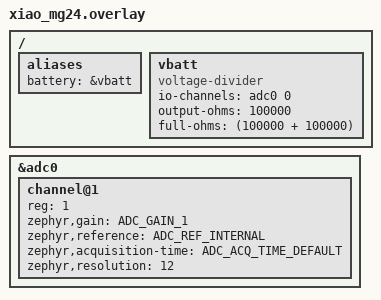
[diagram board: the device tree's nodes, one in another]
/*
 * SPDX-FileCopyrightText: Copyright The Zephyr Project Contributors
 * SPDX-License-Identifier: Apache-2.0
 */

#include <zephyr/dt-bindings/gpio/gpio.h>

/ {
	aliases {
		battery = &vbatt;
	};

	vbatt: vbatt {
		compatible = "voltage-divider";
		io-channels = <&adc0 0>;
		output-ohms = <100000>;
		full-ohms = <(100000 + 100000)>;
	};
};

&adc0 {
	status = "okay";
	#address-cells = <1>;
	#size-cells = <0>;

	channel@1 {
		reg = <1>;
		zephyr,gain = "ADC_GAIN_1";
		zephyr,reference = "ADC_REF_INTERNAL";
		zephyr,acquisition-time = <ADC_ACQ_TIME_DEFAULT>;
		zephyr,resolution = <12>;
	};
};
